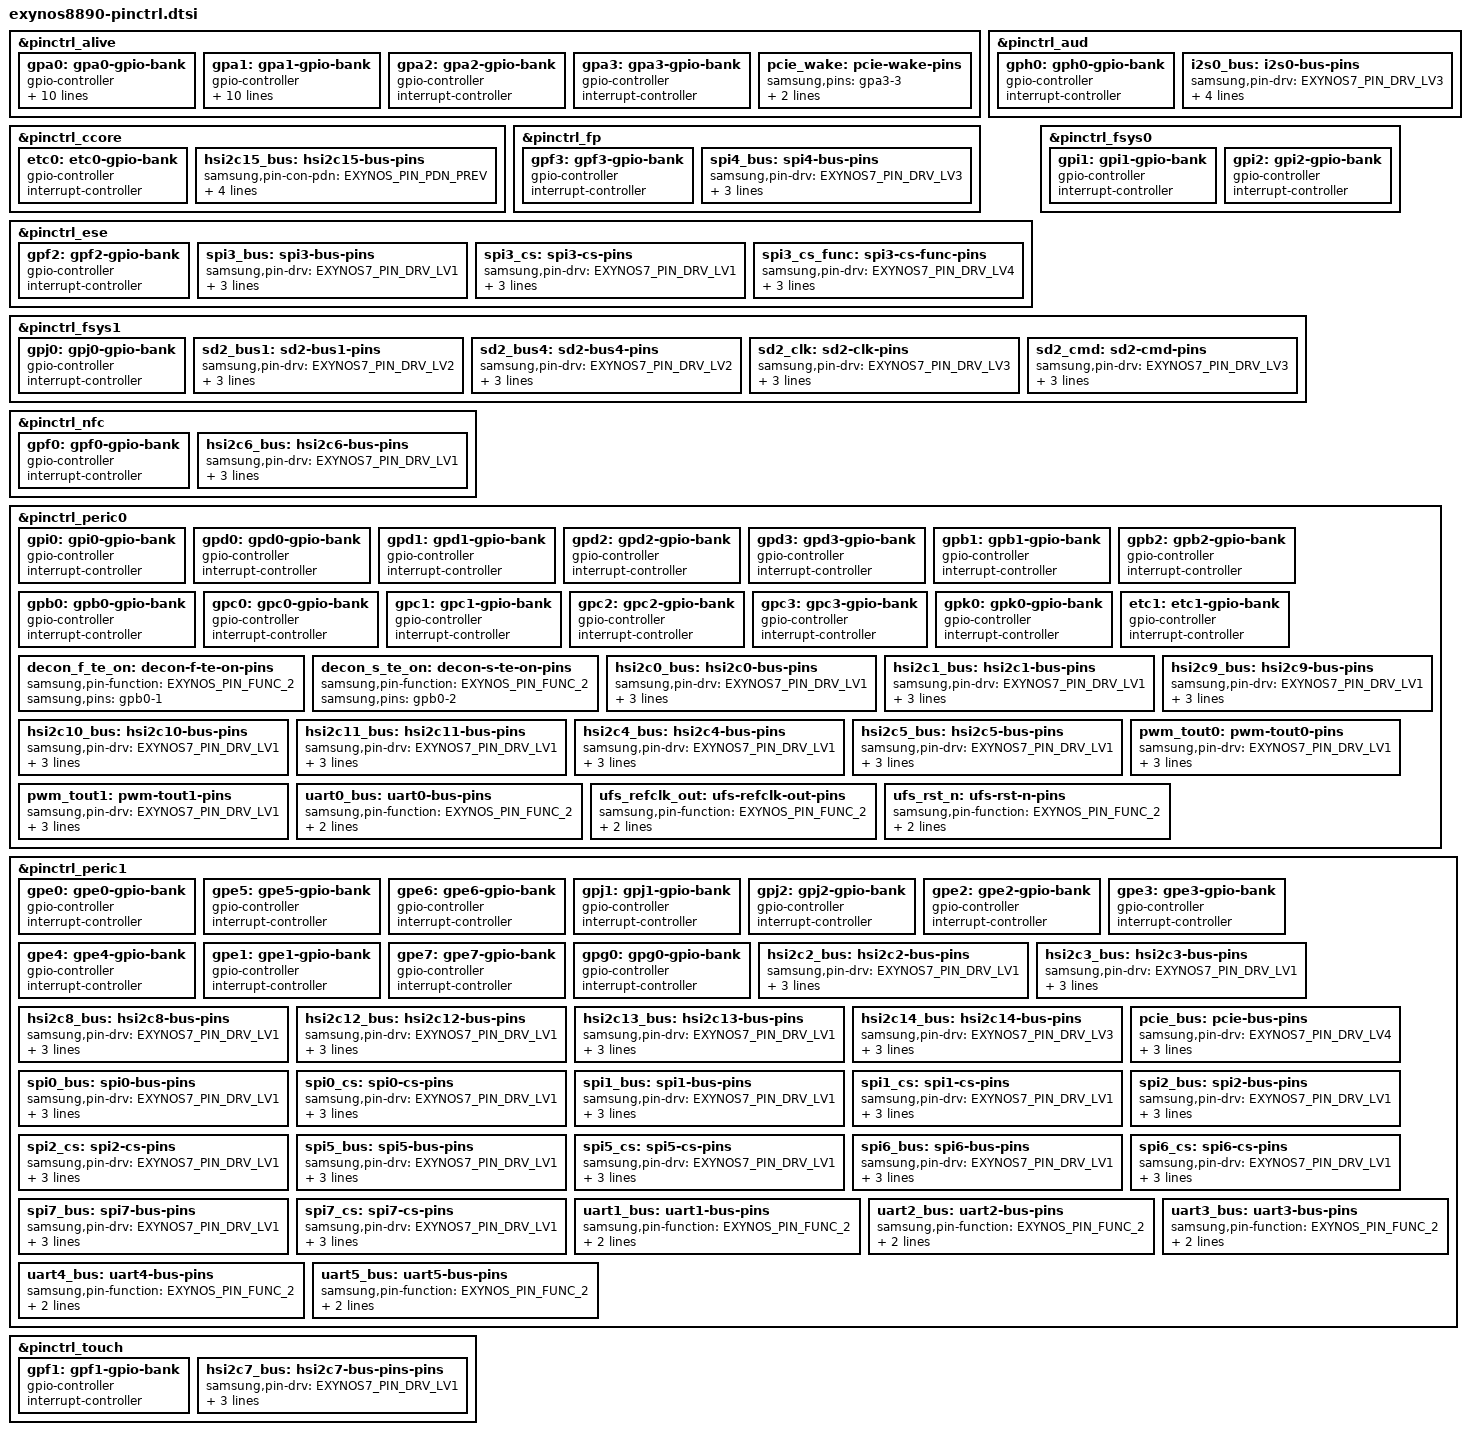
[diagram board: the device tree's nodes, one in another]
// SPDX-License-Identifier: GPL-2.0 OR BSD-3-Clause
/*
 * Samsung's Exynos 8890 SoC pin-mux and pin-config device tree source
 *
 * Copyright (c) 2025, Ivaylo Ivanov <ivo.ivanov.ivanov1@gmail.com>
 */

#include <dt-bindings/interrupt-controller/arm-gic.h>
#include "exynos-pinctrl.h"

&pinctrl_alive {
	gpa0: gpa0-gpio-bank {
		gpio-controller;
		#gpio-cells = <2>;

		interrupt-controller;
		#interrupt-cells = <2>;
		interrupt-parent = <&gic>;
		interrupts = <GIC_SPI 0 IRQ_TYPE_LEVEL_HIGH>,
			     <GIC_SPI 1 IRQ_TYPE_LEVEL_HIGH>,
			     <GIC_SPI 2 IRQ_TYPE_LEVEL_HIGH>,
			     <GIC_SPI 3 IRQ_TYPE_LEVEL_HIGH>,
			     <GIC_SPI 4 IRQ_TYPE_LEVEL_HIGH>,
			     <GIC_SPI 5 IRQ_TYPE_LEVEL_HIGH>,
			     <GIC_SPI 6 IRQ_TYPE_LEVEL_HIGH>,
			     <GIC_SPI 7 IRQ_TYPE_LEVEL_HIGH>;
	};

	gpa1: gpa1-gpio-bank {
		gpio-controller;
		#gpio-cells = <2>;

		interrupt-controller;
		#interrupt-cells = <2>;
		interrupt-parent = <&gic>;
		interrupts = <GIC_SPI 8 IRQ_TYPE_LEVEL_HIGH>,
			     <GIC_SPI 9 IRQ_TYPE_LEVEL_HIGH>,
			     <GIC_SPI 10 IRQ_TYPE_LEVEL_HIGH>,
			     <GIC_SPI 11 IRQ_TYPE_LEVEL_HIGH>,
			     <GIC_SPI 12 IRQ_TYPE_LEVEL_HIGH>,
			     <GIC_SPI 13 IRQ_TYPE_LEVEL_HIGH>,
			     <GIC_SPI 14 IRQ_TYPE_LEVEL_HIGH>,
			     <GIC_SPI 15 IRQ_TYPE_LEVEL_HIGH>;
	};


	gpa2: gpa2-gpio-bank {
		gpio-controller;
		#gpio-cells = <2>;

		interrupt-controller;
		#interrupt-cells = <2>;
	};

	gpa3: gpa3-gpio-bank {
		gpio-controller;
		#gpio-cells = <2>;

		interrupt-controller;
		#interrupt-cells = <2>;
	};

	pcie_wake: pcie-wake-pins {
		samsung,pins = "gpa3-3";
		samsung,pin-function = <EXYNOS_PIN_FUNC_INPUT>;
		samsung,pin-pud = <EXYNOS_PIN_PULL_NONE>;
	};
};

&pinctrl_aud {
	gph0: gph0-gpio-bank {
		gpio-controller;
		#gpio-cells = <2>;

		interrupt-controller;
		#interrupt-cells = <2>;
	};

	i2s0_bus: i2s0-bus-pins {
		samsung,pin-drv = <EXYNOS7_PIN_DRV_LV3>;
		samsung,pin-function = <EXYNOS_PIN_FUNC_2>;
		samsung,pin-pud = <EXYNOS_PIN_PULL_DOWN>;
		samsung,pins = "gph0-0", "gph0-1", "gph0-2", "gph0-3",
			       "gph0-4", "gph0-5", "gph0-6";
	};
};

&pinctrl_ccore {
	etc0: etc0-gpio-bank {
		gpio-controller;
		#gpio-cells = <2>;

		interrupt-controller;
		#interrupt-cells = <2>;
	};

	hsi2c15_bus: hsi2c15-bus-pins {
		samsung,pin-con-pdn = <EXYNOS_PIN_PDN_PREV>;
		samsung,pin-drv = <EXYNOS7_PIN_DRV_LV1>;
		samsung,pin-function = <EXYNOS_PIN_FUNC_2>;
		samsung,pin-pud = <EXYNOS_PIN_PULL_NONE>;
		samsung,pins = "etc0-1", "etc0-0";
	};
};

&pinctrl_fp {
	gpf3: gpf3-gpio-bank {
		gpio-controller;
		#gpio-cells = <2>;

		interrupt-controller;
		#interrupt-cells = <2>;
	};

	spi4_bus: spi4-bus-pins {
		samsung,pin-drv = <EXYNOS7_PIN_DRV_LV3>;
		samsung,pin-function = <EXYNOS_PIN_FUNC_2>;
		samsung,pin-pud = <EXYNOS_PIN_PULL_UP>;
		samsung,pins = "gpf3-3", "gpf3-2", "gpf3-1", "gpf3-0";
	};
};

&pinctrl_ese {
	gpf2: gpf2-gpio-bank {
		gpio-controller;
		#gpio-cells = <2>;

		interrupt-controller;
		#interrupt-cells = <2>;
	};

	spi3_bus: spi3-bus-pins {
		samsung,pin-drv = <EXYNOS7_PIN_DRV_LV1>;
		samsung,pin-function = <EXYNOS_PIN_FUNC_2>;
		samsung,pin-pud = <EXYNOS_PIN_PULL_NONE>;
		samsung,pins = "gpf2-3", "gpf2-2", "gpf2-0";
	};

	spi3_cs: spi3-cs-pins {
		samsung,pin-drv = <EXYNOS7_PIN_DRV_LV1>;
		samsung,pin-function = <EXYNOS_PIN_FUNC_OUTPUT>;
		samsung,pin-pud = <EXYNOS_PIN_PULL_UP>;
		samsung,pins = "gpf2-1";
	};

	spi3_cs_func: spi3-cs-func-pins {
		samsung,pin-drv = <EXYNOS7_PIN_DRV_LV4>;
		samsung,pin-function = <EXYNOS_PIN_FUNC_2>;
		samsung,pin-pud = <EXYNOS_PIN_PULL_UP>;
		samsung,pins = "gpf2-1";
	};
};

&pinctrl_fsys0 {
	gpi1: gpi1-gpio-bank {
		gpio-controller;
		#gpio-cells = <2>;

		interrupt-controller;
		#interrupt-cells = <2>;
	};

	gpi2: gpi2-gpio-bank {
		gpio-controller;
		#gpio-cells = <2>;

		interrupt-controller;
		#interrupt-cells = <2>;
	};
};

&pinctrl_fsys1 {
	gpj0: gpj0-gpio-bank {
		gpio-controller;
		#gpio-cells = <2>;

		interrupt-controller;
		#interrupt-cells = <2>;
	};

	sd2_bus1: sd2-bus1-pins {
		samsung,pin-drv = <EXYNOS7_PIN_DRV_LV2>;
		samsung,pin-function = <EXYNOS_PIN_FUNC_2>;
		samsung,pin-pud = <EXYNOS_PIN_PULL_NONE>;
		samsung,pins = "gpj0-3";
	};

	sd2_bus4: sd2-bus4-pins {
		samsung,pin-drv = <EXYNOS7_PIN_DRV_LV2>;
		samsung,pin-function = <EXYNOS_PIN_FUNC_2>;
		samsung,pin-pud = <EXYNOS_PIN_PULL_NONE>;
		samsung,pins = "gpj0-4", "gpj0-5", "gpj0-6";
	};

	sd2_clk: sd2-clk-pins {
		samsung,pin-drv = <EXYNOS7_PIN_DRV_LV3>;
		samsung,pin-function = <EXYNOS_PIN_FUNC_2>;
		samsung,pin-pud = <EXYNOS_PIN_PULL_NONE>;
		samsung,pins = "gpj0-0";
	};

	sd2_cmd: sd2-cmd-pins {
		samsung,pin-drv = <EXYNOS7_PIN_DRV_LV3>;
		samsung,pin-function = <EXYNOS_PIN_FUNC_2>;
		samsung,pin-pud = <EXYNOS_PIN_PULL_NONE>;
		samsung,pins = "gpj0-1";
	};
};

&pinctrl_nfc {
	gpf0: gpf0-gpio-bank {
		gpio-controller;
		#gpio-cells = <2>;

		interrupt-controller;
		#interrupt-cells = <2>;
	};

	hsi2c6_bus: hsi2c6-bus-pins {
		samsung,pin-drv = <EXYNOS7_PIN_DRV_LV1>;
		samsung,pin-function = <EXYNOS_PIN_FUNC_2>;
		samsung,pin-pud = <EXYNOS_PIN_PULL_NONE>;
		samsung,pins = "gpf0-1", "gpf0-0";
	};
};

&pinctrl_peric0 {
	gpi0: gpi0-gpio-bank {
		gpio-controller;
		#gpio-cells = <2>;

		interrupt-controller;
		#interrupt-cells = <2>;
	};

	gpd0: gpd0-gpio-bank {
		gpio-controller;
		#gpio-cells = <2>;

		interrupt-controller;
		#interrupt-cells = <2>;
	};

	gpd1: gpd1-gpio-bank {
		gpio-controller;
		#gpio-cells = <2>;

		interrupt-controller;
		#interrupt-cells = <2>;
	};

	gpd2: gpd2-gpio-bank {
		gpio-controller;
		#gpio-cells = <2>;

		interrupt-controller;
		#interrupt-cells = <2>;
	};

	gpd3: gpd3-gpio-bank {
		gpio-controller;
		#gpio-cells = <2>;

		interrupt-controller;
		#interrupt-cells = <2>;
	};

	gpb1: gpb1-gpio-bank {
		gpio-controller;
		#gpio-cells = <2>;

		interrupt-controller;
		#interrupt-cells = <2>;
	};

	gpb2: gpb2-gpio-bank {
		gpio-controller;
		#gpio-cells = <2>;

		interrupt-controller;
		#interrupt-cells = <2>;
	};

	gpb0: gpb0-gpio-bank {
		gpio-controller;
		#gpio-cells = <2>;

		interrupt-controller;
		#interrupt-cells = <2>;
	};

	gpc0: gpc0-gpio-bank {
		gpio-controller;
		#gpio-cells = <2>;

		interrupt-controller;
		#interrupt-cells = <2>;
	};

	gpc1: gpc1-gpio-bank {
		gpio-controller;
		#gpio-cells = <2>;

		interrupt-controller;
		#interrupt-cells = <2>;
	};

	gpc2: gpc2-gpio-bank {
		gpio-controller;
		#gpio-cells = <2>;

		interrupt-controller;
		#interrupt-cells = <2>;
	};

	gpc3: gpc3-gpio-bank {
		gpio-controller;
		#gpio-cells = <2>;

		interrupt-controller;
		#interrupt-cells = <2>;
	};


	gpk0: gpk0-gpio-bank {
		gpio-controller;
		#gpio-cells = <2>;

		interrupt-controller;
		#interrupt-cells = <2>;
	};

	etc1: etc1-gpio-bank {
		gpio-controller;
		#gpio-cells = <2>;

		interrupt-controller;
		#interrupt-cells = <2>;
	};

	decon_f_te_on: decon-f-te-on-pins {
		samsung,pin-function = <EXYNOS_PIN_FUNC_2>;
		samsung,pins = "gpb0-1";
	};

	decon_s_te_on: decon-s-te-on-pins {
		samsung,pin-function = <EXYNOS_PIN_FUNC_2>;
		samsung,pins = "gpb0-2";
	};

	hsi2c0_bus: hsi2c0-bus-pins {
		samsung,pin-drv = <EXYNOS7_PIN_DRV_LV1>;
		samsung,pin-function = <EXYNOS_PIN_FUNC_2>;
		samsung,pin-pud = <EXYNOS_PIN_PULL_NONE>;
		samsung,pins = "gpd1-1", "gpd1-0";
	};

	hsi2c1_bus: hsi2c1-bus-pins {
		samsung,pin-drv = <EXYNOS7_PIN_DRV_LV1>;
		samsung,pin-function = <EXYNOS_PIN_FUNC_2>;
		samsung,pin-pud = <EXYNOS_PIN_PULL_NONE>;
		samsung,pins = "gpd1-3", "gpd1-2";
	};

	hsi2c9_bus: hsi2c9-bus-pins {
		samsung,pin-drv = <EXYNOS7_PIN_DRV_LV1>;
		samsung,pin-function = <EXYNOS_PIN_FUNC_2>;
		samsung,pin-pud = <EXYNOS_PIN_PULL_NONE>;
		samsung,pins = "gpd1-5", "gpd1-4";
	};

	hsi2c10_bus: hsi2c10-bus-pins {
		samsung,pin-drv = <EXYNOS7_PIN_DRV_LV1>;
		samsung,pin-function = <EXYNOS_PIN_FUNC_2>;
		samsung,pin-pud = <EXYNOS_PIN_PULL_NONE>;
		samsung,pins = "gpd2-1", "gpd2-0";
	};

	hsi2c11_bus: hsi2c11-bus-pins {
		samsung,pin-drv = <EXYNOS7_PIN_DRV_LV1>;
		samsung,pin-function = <EXYNOS_PIN_FUNC_2>;
		samsung,pin-pud = <EXYNOS_PIN_PULL_NONE>;
		samsung,pins = "gpd2-3", "gpd2-2";
	};

	hsi2c4_bus: hsi2c4-bus-pins {
		samsung,pin-drv = <EXYNOS7_PIN_DRV_LV1>;
		samsung,pin-function = <EXYNOS_PIN_FUNC_2>;
		samsung,pin-pud = <EXYNOS_PIN_PULL_NONE>;
		samsung,pins = "gpd3-1", "gpd3-0";
	};

	hsi2c5_bus: hsi2c5-bus-pins {
		samsung,pin-drv = <EXYNOS7_PIN_DRV_LV1>;
		samsung,pin-function = <EXYNOS_PIN_FUNC_2>;
		samsung,pin-pud = <EXYNOS_PIN_PULL_NONE>;
		samsung,pins = "gpd3-3", "gpd3-2";
	};

	pwm_tout0: pwm-tout0-pins {
		samsung,pin-drv = <EXYNOS7_PIN_DRV_LV1>;
		samsung,pin-function = <EXYNOS_PIN_FUNC_2>;
		samsung,pin-pud = <EXYNOS_PIN_PULL_DOWN>;
		samsung,pins = "gpd0-4";
	};

	pwm_tout1: pwm-tout1-pins {
		samsung,pin-drv = <EXYNOS7_PIN_DRV_LV1>;
		samsung,pin-function = <EXYNOS_PIN_FUNC_2>;
		samsung,pin-pud = <EXYNOS_PIN_PULL_DOWN>;
		samsung,pins = "gpd0-5";
	};

	uart0_bus: uart0-bus-pins {
		samsung,pin-function = <EXYNOS_PIN_FUNC_2>;
		samsung,pin-pud = <EXYNOS_PIN_PULL_NONE>;
		samsung,pins = "gpd0-3", "gpd0-2", "gpd0-1", "gpd0-0";
	};


	ufs_refclk_out: ufs-refclk-out-pins {
		samsung,pin-function = <EXYNOS_PIN_FUNC_2>;
		samsung,pin-pud = <EXYNOS_PIN_PULL_NONE>;
		samsung,pins = "gpi0-5";
	};

	ufs_rst_n: ufs-rst-n-pins {
		samsung,pin-function = <EXYNOS_PIN_FUNC_2>;
		samsung,pin-pud = <EXYNOS_PIN_PULL_NONE>;
		samsung,pins = "gpi0-4";
	};
};

&pinctrl_peric1 {
	gpe0: gpe0-gpio-bank {
		gpio-controller;
		#gpio-cells = <2>;

		interrupt-controller;
		#interrupt-cells = <2>;
	};

	gpe5: gpe5-gpio-bank {
		gpio-controller;
		#gpio-cells = <2>;

		interrupt-controller;
		#interrupt-cells = <2>;
	};

	gpe6: gpe6-gpio-bank {
		gpio-controller;
		#gpio-cells = <2>;

		interrupt-controller;
		#interrupt-cells = <2>;
	};

	gpj1: gpj1-gpio-bank {
		gpio-controller;
		#gpio-cells = <2>;

		interrupt-controller;
		#interrupt-cells = <2>;
	};

	gpj2: gpj2-gpio-bank {
		gpio-controller;
		#gpio-cells = <2>;

		interrupt-controller;
		#interrupt-cells = <2>;
	};

	gpe2: gpe2-gpio-bank {
		gpio-controller;
		#gpio-cells = <2>;

		interrupt-controller;
		#interrupt-cells = <2>;
	};

	gpe3: gpe3-gpio-bank {
		gpio-controller;
		#gpio-cells = <2>;

		interrupt-controller;
		#interrupt-cells = <2>;
	};

	gpe4: gpe4-gpio-bank {
		gpio-controller;
		#gpio-cells = <2>;

		interrupt-controller;
		#interrupt-cells = <2>;
	};

	gpe1: gpe1-gpio-bank {
		gpio-controller;
		#gpio-cells = <2>;

		interrupt-controller;
		#interrupt-cells = <2>;
	};

	gpe7: gpe7-gpio-bank {
		gpio-controller;
		#gpio-cells = <2>;

		interrupt-controller;
		#interrupt-cells = <2>;
	};

	gpg0: gpg0-gpio-bank {
		gpio-controller;
		#gpio-cells = <2>;

		interrupt-controller;
		#interrupt-cells = <2>;
	};


	hsi2c2_bus: hsi2c2-bus-pins {
		samsung,pin-drv = <EXYNOS7_PIN_DRV_LV1>;
		samsung,pin-function = <EXYNOS_PIN_FUNC_2>;
		samsung,pin-pud = <EXYNOS_PIN_PULL_NONE>;
		samsung,pins = "gpe5-1", "gpe5-0";
	};

	hsi2c3_bus: hsi2c3-bus-pins {
		samsung,pin-drv = <EXYNOS7_PIN_DRV_LV1>;
		samsung,pin-function = <EXYNOS_PIN_FUNC_2>;
		samsung,pin-pud = <EXYNOS_PIN_PULL_NONE>;
		samsung,pins = "gpe5-3", "gpe5-2";
	};

	hsi2c8_bus: hsi2c8-bus-pins {
		samsung,pin-drv = <EXYNOS7_PIN_DRV_LV1>;
		samsung,pin-function = <EXYNOS_PIN_FUNC_2>;
		samsung,pin-pud = <EXYNOS_PIN_PULL_NONE>;
		samsung,pins = "gpe5-5", "gpe5-4";
	};

	hsi2c12_bus: hsi2c12-bus-pins {
		samsung,pin-drv = <EXYNOS7_PIN_DRV_LV1>;
		samsung,pin-function = <EXYNOS_PIN_FUNC_2>;
		samsung,pin-pud = <EXYNOS_PIN_PULL_NONE>;
		samsung,pins = "gpe5-7", "gpe5-6";
	};

	hsi2c13_bus: hsi2c13-bus-pins {
		samsung,pin-drv = <EXYNOS7_PIN_DRV_LV1>;
		samsung,pin-function = <EXYNOS_PIN_FUNC_2>;
		samsung,pin-pud = <EXYNOS_PIN_PULL_NONE>;
		samsung,pins = "gpe6-1", "gpe6-0";
	};

	hsi2c14_bus: hsi2c14-bus-pins {
		samsung,pin-drv = <EXYNOS7_PIN_DRV_LV3>;
		samsung,pin-function = <EXYNOS_PIN_FUNC_2>;
		samsung,pin-pud = <EXYNOS_PIN_PULL_NONE>;
		samsung,pins = "gpe6-3", "gpe6-2";
	};

	pcie_bus: pcie-bus-pins {
		samsung,pin-drv = <EXYNOS7_PIN_DRV_LV4>;
		samsung,pin-function = <EXYNOS_PIN_FUNC_INPUT>;
		samsung,pin-pud = <EXYNOS_PIN_PULL_UP>;
		samsung,pins = "gpj1-0", "gpj1-1", "gpj1-2";
	};

	spi0_bus: spi0-bus-pins {
		samsung,pin-drv = <EXYNOS7_PIN_DRV_LV1>;
		samsung,pin-function = <EXYNOS_PIN_FUNC_2>;
		samsung,pin-pud = <EXYNOS_PIN_PULL_UP>;
		samsung,pins = "gpe2-3", "gpe2-2", "gpe2-0";
	};

	spi0_cs: spi0-cs-pins {
		samsung,pin-drv = <EXYNOS7_PIN_DRV_LV1>;
		samsung,pin-function = <EXYNOS_PIN_FUNC_OUTPUT>;
		samsung,pin-pud = <EXYNOS_PIN_PULL_UP>;
		samsung,pins = "gpe2-1";
	};

	spi1_bus: spi1-bus-pins {
		samsung,pin-drv = <EXYNOS7_PIN_DRV_LV1>;
		samsung,pin-function = <EXYNOS_PIN_FUNC_2>;
		samsung,pin-pud = <EXYNOS_PIN_PULL_UP>;
		samsung,pins = "gpe2-7", "gpe2-6", "gpe2-4";
	};

	spi1_cs: spi1-cs-pins {
		samsung,pin-drv = <EXYNOS7_PIN_DRV_LV1>;
		samsung,pin-function = <EXYNOS_PIN_FUNC_OUTPUT>;
		samsung,pin-pud = <EXYNOS_PIN_PULL_UP>;
		samsung,pins = "gpe2-5";
	};

	spi2_bus: spi2-bus-pins {
		samsung,pin-drv = <EXYNOS7_PIN_DRV_LV1>;
		samsung,pin-function = <EXYNOS_PIN_FUNC_2>;
		samsung,pin-pud = <EXYNOS_PIN_PULL_UP>;
		samsung,pins = "gpe3-2", "gpe3-0";
	};

	spi2_cs: spi2-cs-pins {
		samsung,pin-drv = <EXYNOS7_PIN_DRV_LV1>;
		samsung,pin-function = <EXYNOS_PIN_FUNC_OUTPUT>;
		samsung,pin-pud = <EXYNOS_PIN_PULL_UP>;
		samsung,pins = "gpe3-1";
	};

	spi5_bus: spi5-bus-pins {
		samsung,pin-drv = <EXYNOS7_PIN_DRV_LV1>;
		samsung,pin-function = <EXYNOS_PIN_FUNC_2>;
		samsung,pin-pud = <EXYNOS_PIN_PULL_UP>;
		samsung,pins = "gpe3-7", "gpe3-6", "gpe3-4";
	};

	spi5_cs: spi5-cs-pins {
		samsung,pin-drv = <EXYNOS7_PIN_DRV_LV1>;
		samsung,pin-function = <EXYNOS_PIN_FUNC_OUTPUT>;
		samsung,pin-pud = <EXYNOS_PIN_PULL_UP>;
		samsung,pins = "gpe3-5";
	};

	spi6_bus: spi6-bus-pins {
		samsung,pin-drv = <EXYNOS7_PIN_DRV_LV1>;
		samsung,pin-function = <EXYNOS_PIN_FUNC_2>;
		samsung,pin-pud = <EXYNOS_PIN_PULL_UP>;
		samsung,pins = "gpe4-3", "gpe4-2", "gpe4-0";
	};

	spi6_cs: spi6-cs-pins {
		samsung,pin-drv = <EXYNOS7_PIN_DRV_LV1>;
		samsung,pin-function = <EXYNOS_PIN_FUNC_OUTPUT>;
		samsung,pin-pud = <EXYNOS_PIN_PULL_UP>;
		samsung,pins = "gpe4-1";
	};

	spi7_bus: spi7-bus-pins {
		samsung,pin-drv = <EXYNOS7_PIN_DRV_LV1>;
		samsung,pin-function = <EXYNOS_PIN_FUNC_2>;
		samsung,pin-pud = <EXYNOS_PIN_PULL_UP>;
		samsung,pins = "gpe4-7", "gpe4-6", "gpe4-4";
	};

	spi7_cs: spi7-cs-pins {
		samsung,pin-drv = <EXYNOS7_PIN_DRV_LV1>;
		samsung,pin-function = <EXYNOS_PIN_FUNC_OUTPUT>;
		samsung,pin-pud = <EXYNOS_PIN_PULL_UP>;
		samsung,pins = "gpe4-5";
	};

	uart1_bus: uart1-bus-pins {
		samsung,pin-function = <EXYNOS_PIN_FUNC_2>;
		samsung,pin-pud = <EXYNOS_PIN_PULL_NONE>;
		samsung,pins = "gpe0-3", "gpe0-2", "gpe0-1", "gpe0-0";
	};

	uart2_bus: uart2-bus-pins {
		samsung,pin-function = <EXYNOS_PIN_FUNC_2>;
		samsung,pin-pud = <EXYNOS_PIN_PULL_NONE>;
		samsung,pins = "gpe0-5", "gpe0-4";
	};

	uart3_bus: uart3-bus-pins {
		samsung,pin-function = <EXYNOS_PIN_FUNC_2>;
		samsung,pin-pud = <EXYNOS_PIN_PULL_NONE>;
		samsung,pins = "gpe0-7", "gpe0-6";
	};

	uart4_bus: uart4-bus-pins {
		samsung,pin-function = <EXYNOS_PIN_FUNC_2>;
		samsung,pin-pud = <EXYNOS_PIN_PULL_NONE>;
		samsung,pins = "gpe1-3", "gpe1-2", "gpe1-1", "gpe1-0";
	};

	uart5_bus: uart5-bus-pins {
		samsung,pin-function = <EXYNOS_PIN_FUNC_2>;
		samsung,pin-pud = <EXYNOS_PIN_PULL_NONE>;
		samsung,pins = "gpe1-7", "gpe1-6", "gpe1-5", "gpe1-4";
	};
};

&pinctrl_touch {
	gpf1: gpf1-gpio-bank {
		gpio-controller;
		#gpio-cells = <2>;

		interrupt-controller;
		#interrupt-cells = <2>;
	};

	hsi2c7_bus: hsi2c7-bus-pins-pins {
		samsung,pin-drv = <EXYNOS7_PIN_DRV_LV1>;
		samsung,pin-function = <EXYNOS_PIN_FUNC_2>;
		samsung,pin-pud = <EXYNOS_PIN_PULL_NONE>;
		samsung,pins = "gpf1-1", "gpf1-0";
	};
};
